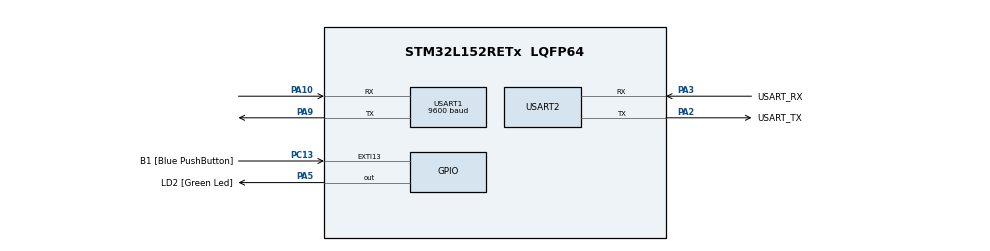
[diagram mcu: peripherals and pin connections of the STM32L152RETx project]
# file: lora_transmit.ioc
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Mcu.Family=STM32L1
Mcu.Name=STM32L152RETx
Mcu.Package=LQFP64
NVIC.PriorityGroup=NVIC_PRIORITYGROUP_0
PA10.Mode=Asynchronous
PA10.Signal=USART1_RX
PA13.GPIO_Label=TMS
PA13.Mode=Serial_Wire
PA13.Signal=SYS_JTMS-SWDIO
PA14.GPIO_Label=TCK
PA14.Mode=Serial_Wire
PA14.Signal=SYS_JTCK-SWCLK
PA2.GPIO_Label=USART_TX
PA2.Mode=Asynchronous
PA2.Signal=USART2_TX
PA3.GPIO_Label=USART_RX
PA3.Mode=Asynchronous
PA3.Signal=USART2_RX
PA5.GPIO_Label=LD2 [Green Led]
PA5.Signal=GPIO_Output
PA9.Mode=Asynchronous
PA9.Signal=USART1_TX
PB3.GPIO_Label=SWO
PB3.Signal=SYS_JTDO-TRACESWO
PC13-WKUP2.GPIO_Label=B1 [Blue PushButton]
PC13-WKUP2.Signal=GPXTI13
PC14-OSC32_IN.Mode=LSE-External-Oscillator
PC14-OSC32_IN.Signal=RCC_OSC32_IN
PC15-OSC32_OUT.Mode=LSE-External-Oscillator
PC15-OSC32_OUT.Signal=RCC_OSC32_OUT
PH0-OSC_IN.Mode=HSE-External-Clock-Source
PH0-OSC_IN.Signal=RCC_OSC_IN
PH1-OSC_OUT.Signal=RCC_OSC_OUT
ProjectManager.HeapSize=0x200
ProjectManager.StackSize=0x400
ProjectManager.TargetToolchain=STM32CubeIDE
RCC.48MHZClocksFreq_Value=48000000
RCC.AHBFreq_Value=32000000
RCC.APB1Freq_Value=32000000
RCC.APB1TimFreq_Value=32000000
RCC.APB2Freq_Value=32000000
RCC.APB2TimFreq_Value=32000000
RCC.HCLKFreq_Value=32000000
RCC.HSE_VALUE=8000000
RCC.HSI_VALUE=16000000
RCC.MSI_VALUE=2097000
RCC.PLLDIV=RCC_PLL_DIV3
RCC.PLLMUL=RCC_PLL_MUL6
RCC.RTCClockSelectionVirtual=RCC_RTCCLKSOURCE_LSE
RCC.SYSCLKFreq_VALUE=32000000
RCC.SYSCLKSource=RCC_SYSCLKSOURCE_PLLCLK
RCC.USBOutput=48000000
RCC.VCOOutputFreq_Value=96000000
USART1.BaudRate=9600
USART1.VirtualMode=VM_ASYNC
USART2.VirtualMode=VM_ASYNC
board=NUCLEO-L152RE

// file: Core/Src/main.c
/* USER CODE BEGIN Header */
/**
  **************************
  * @file           : main.c
  * @brief          : Main program body
  **************************
  * @attention
  *
  * Copyright (c) 2024 STMicroelectronics.
  * All rights reserved.²
  *
  * This software is licensed under terms that can be found in the LICENSE file
  * in the root directory of this software component.
  * If no LICENSE file comes with this software, it is provided AS-IS.
  *
  **************************
  */
/* USER CODE END Header */
#include "main.h"
#include "usart.h"
#include "gpio.h"

/* USER CODE BEGIN PTD */

//#define MODE_TRANSMITTER 0
//#define MODE_RECEIVER 1

/* USER CODE END PTD */

void SystemClock_Config(void);

/* USER CODE BEGIN 0 */

char receivedData[1000]; // Pour stocker le caractère reçu

/* USER CODE END 0 */

int main(void)
{

  /* MCU Configuration--------------------------------------------------------*/

  /* Reset of all peripherals, Initializes the Flash interface and the Systick. */
  HAL_Init();

  /* Configure the system clock */
  SystemClock_Config();

  /* Initialize all configured peripherals */
  MX_GPIO_Init();
  MX_USART2_UART_Init();
  MX_USART1_UART_Init();
  //MX_I2C1_Init();
  /* USER CODE BEGIN 2 */
/*
  // Transmit command to LoRa module
  	  HAL_UART_Transmit(&huart1, (uint8_t*)dataToSend, strlen(dataToSend), 1000);

     // Wait for response from LoRa module
     HAL_UART_Receive(&huart1, (uint8_t*)receivedData, sizeof(receivedData), 1000);

*/

  // Transmit command at to LoRa module
         char dataToSend[] = "AT\r"; // Tableau d'octets à envoyer

  	   	  HAL_UART_Transmit(&huart1, (uint8_t*)dataToSend, strlen(dataToSend), 1000);
  	  // Attente de la réponse à la première commande
  	     HAL_UART_Receive(&huart1, (uint8_t*)receivedData, sizeof(receivedData), 1000);

  	     // Transmission de la réponse reçue à une autre UART (si nécessaire)
  	     HAL_UART_Transmit(&huart2, (uint8_t*)receivedData, strlen(receivedData), 1000);
/*
  	     // Envoi de la deuxième commande "AT+ID"
  	     char secondCommand[] = "AT+ID\r";
  	     HAL_UART_Transmit(&huart1, (uint8_t*)secondCommand, strlen(secondCommand), 1000);

  	     // Attente de la réponse à la deuxième commande (si nécessaire)
  	     HAL_UART_Receive(&huart1, (uint8_t*)receivedData, sizeof(receivedData), 1000);
  	   // Transmission de la réponse reçue à une autre UART (si nécessaire)
  	     HAL_UART_Transmit(&huart2, (uint8_t*)receivedData, strlen(receivedData), 1000);
*/

  	   // Envoi de la 3ème commande "AT+MODE"
  	    char thirdCommand[] = "AT+MODE=TEST\r";
  	    HAL_UART_Transmit(&huart1, (uint8_t*)thirdCommand, strlen(thirdCommand), 1000);

  	    // Attente de la réponse à la 3ième commande (si nécessaire)
  	    HAL_UART_Receive(&huart1, (uint8_t*)receivedData, sizeof(receivedData), 1000);
  	    // Transmission de la réponse reçue à une autre UART (si nécessaire)
  	    HAL_UART_Transmit(&huart2, (uint8_t*)receivedData, strlen(receivedData), 1000);

  /* USER CODE END 2 */

  /* Infinite loop */
  /* USER CODE BEGIN WHILE */
  while (1)
  {
	  // Envoi de la commande  AT+TEST=TXLRSTR (ascii) pour envoyer un message
	 //                        AT+TEST=TXLRPKT (hexa)
	    	  char sendCommand[] = "AT+TEST=TXLRPKT AC1234\r";
	    	  HAL_UART_Transmit(&huart1, (uint8_t*)sendCommand, strlen(sendCommand), 1000);

	    	  // Attente de la réponse à la 5ème commande (si nécessaire)
	    	  HAL_UART_Receive(&huart1, (uint8_t*)receivedData, sizeof(receivedData), 1000);
	    	  // Transmission de la réponse reçue à une autre UART (si nécessaire)
	    	  HAL_UART_Transmit(&huart2, (uint8_t*)receivedData, strlen(receivedData), 1000);
	    //	  HAL_Delay(2000);
    /* USER CODE END WHILE */

  }
}

void SystemClock_Config(void)
{
  RCC_OscInitTypeDef RCC_OscInitStruct = {0};
  RCC_ClkInitTypeDef RCC_ClkInitStruct = {0};

  /** Configure the main internal regulator output voltage
  */
  /*if (HAL_PWREx_ControlVoltageScaling(PWR_REGULATOR_VOLTAGE_SCALE1) != HAL_OK)
  {
    Error_Handler();
  }*/

  /** Initializes the RCC Oscillators according to the specified parameters
  * in the RCC_OscInitTypeDef structure.
  */
  RCC_OscInitStruct.OscillatorType = RCC_OSCILLATORTYPE_HSI;
  RCC_OscInitStruct.HSIState = RCC_HSI_ON;
  RCC_OscInitStruct.HSICalibrationValue = RCC_HSICALIBRATION_DEFAULT;
  RCC_OscInitStruct.PLL.PLLState = RCC_PLL_ON;
  RCC_OscInitStruct.PLL.PLLSource = RCC_PLLSOURCE_HSI;
 /* RCC_OscInitStruct.PLL.PLLM = 1;
  RCC_OscInitStruct.PLL.PLLN = 10;
  RCC_OscInitStruct.PLL.PLLP = RCC_PLLP_DIV7;
  RCC_OscInitStruct.PLL.PLLQ = RCC_PLLQ_DIV2;
  RCC_OscInitStruct.PLL.PLLR = RCC_PLLR_DIV2;*/
  if (HAL_RCC_OscConfig(&RCC_OscInitStruct) != HAL_OK)
  {
    Error_Handler();
  }

  /** Initializes the CPU, AHB and APB buses clocks
  */
  RCC_ClkInitStruct.ClockType = RCC_CLOCKTYPE_HCLK|RCC_CLOCKTYPE_SYSCLK
                              |RCC_CLOCKTYPE_PCLK1|RCC_CLOCKTYPE_PCLK2;
  RCC_ClkInitStruct.SYSCLKSource = RCC_SYSCLKSOURCE_PLLCLK;
  RCC_ClkInitStruct.AHBCLKDivider = RCC_SYSCLK_DIV1;
  RCC_ClkInitStruct.APB1CLKDivider = RCC_HCLK_DIV1;
  RCC_ClkInitStruct.APB2CLKDivider = RCC_HCLK_DIV1;

 /* if (HAL_RCC_ClockConfig(&RCC_ClkInitStruct, FLASH_LATENCY_4) != HAL_OK)
  {
    Error_Handler();
  }*/
}

void Error_Handler(void)
{
  __disable_irq();
  while (1)
  {
  }
}
